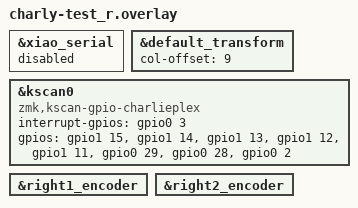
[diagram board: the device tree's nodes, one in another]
/* charly-test_r.overlay */
#include "charly-test.dtsi"

&xiao_serial { status = "disabled"; };

&default_transform {
    col-offset = <9>;
};

&kscan0 {
    compatible = "zmk,kscan-gpio-charlieplex";

    interrupt-gpios = <&gpio0 3 (GPIO_ACTIVE_HIGH | GPIO_PULL_DOWN)>;

    gpios =
        <&gpio1 15 GPIO_ACTIVE_HIGH>,
        <&gpio1 14 GPIO_ACTIVE_HIGH>,
        <&gpio1 13 GPIO_ACTIVE_HIGH>,
        <&gpio1 12 GPIO_ACTIVE_HIGH>,
        <&gpio1 11 GPIO_ACTIVE_HIGH>,
        <&gpio0 29 GPIO_ACTIVE_HIGH>,
        <&gpio0 28 GPIO_ACTIVE_HIGH>,
        <&gpio0  2 GPIO_ACTIVE_HIGH>;
};

&right1_encoder { status = "okay"; };
&right2_encoder { status = "okay"; };

/* 🚫 trackball_listener は右では触らない */
